VERSION ""

NS_ :

BS_:

BU_:

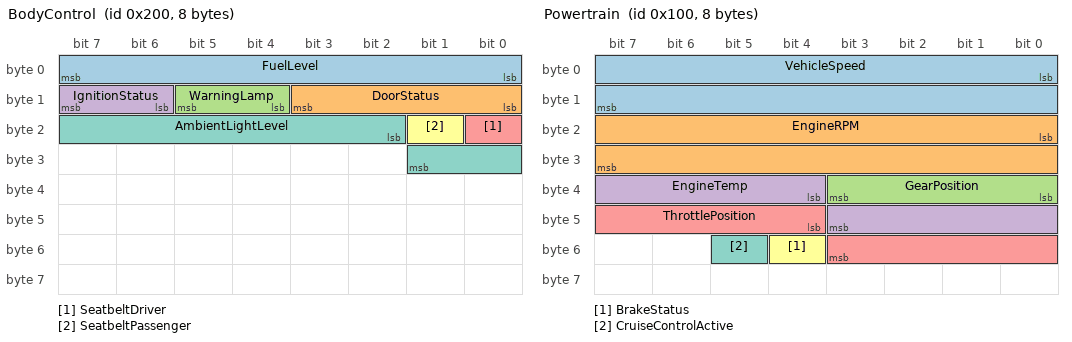
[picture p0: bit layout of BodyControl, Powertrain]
BO_ 512 BodyControl: 8 Vector__XXX
 SG_ FuelLevel : 0|8@1+ (0.392156,0) [0|100] "%" Vector__XXX
 SG_ DoorStatus : 8|4@1+ (1,0) [0|15] "" Vector__XXX
 SG_ WarningLamp : 12|2@1+ (1,0) [0|3] "" Vector__XXX
 SG_ IgnitionStatus : 14|2@1+ (1,0) [0|3] "" Vector__XXX
 SG_ SeatbeltDriver : 16|1@1+ (1,0) [0|1] "" Vector__XXX
 SG_ SeatbeltPassenger : 17|1@1+ (1,0) [0|1] "" Vector__XXX
 SG_ AmbientLightLevel : 18|8@1+ (0.392156,0) [0|100] "%" Vector__XXX

BO_ 256 Powertrain: 8 Vector__XXX
 SG_ VehicleSpeed : 0|16@1+ (0.01,0) [0|250] "km/h" Vector__XXX
 SG_ EngineRPM : 16|16@1+ (0.25,0) [0|8000] "rpm" Vector__XXX
 SG_ GearPosition : 32|4@1+ (1,0) [0|8] "" Vector__XXX
 SG_ EngineTemp : 36|8@1+ (0.5,-40) [-40|210] "degC" Vector__XXX
 SG_ ThrottlePosition : 44|8@1+ (0.392156,0) [0|100] "%" Vector__XXX
 SG_ BrakeStatus : 52|1@1+ (1,0) [0|1] "" Vector__XXX
 SG_ CruiseControlActive : 53|1@1+ (1,0) [0|1] "" Vector__XXX

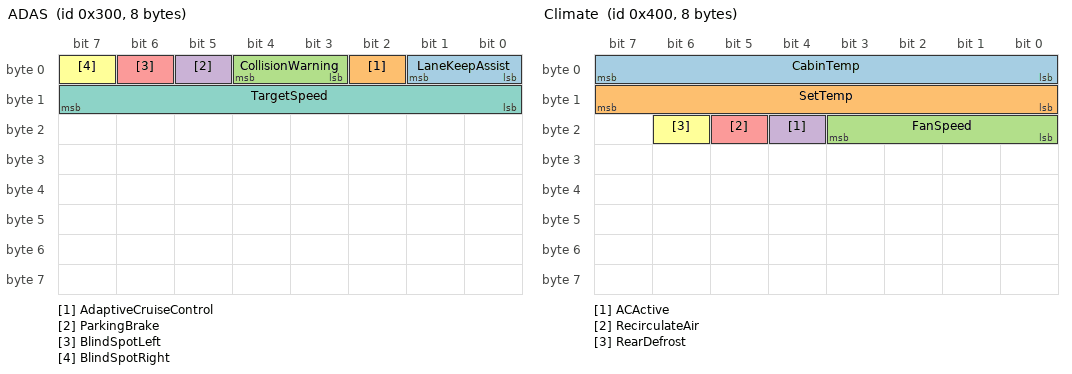
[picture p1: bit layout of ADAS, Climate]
BO_ 768 ADAS: 8 Vector__XXX
 SG_ LaneKeepAssist : 0|2@1+ (1,0) [0|3] "" Vector__XXX
 SG_ AdaptiveCruiseControl : 2|1@1+ (1,0) [0|1] "" Vector__XXX
 SG_ CollisionWarning : 3|2@1+ (1,0) [0|3] "" Vector__XXX
 SG_ ParkingBrake : 5|1@1+ (1,0) [0|1] "" Vector__XXX
 SG_ BlindSpotLeft : 6|1@1+ (1,0) [0|1] "" Vector__XXX
 SG_ BlindSpotRight : 7|1@1+ (1,0) [0|1] "" Vector__XXX
 SG_ TargetSpeed : 8|8@1+ (1,0) [0|250] "km/h" Vector__XXX

BO_ 1024 Climate: 8 Vector__XXX
 SG_ CabinTemp : 0|8@1+ (0.5,-40) [-40|80] "degC" Vector__XXX
 SG_ SetTemp : 8|8@1+ (0.5,-40) [16|30] "degC" Vector__XXX
 SG_ FanSpeed : 16|4@1+ (1,0) [0|7] "" Vector__XXX
 SG_ ACActive : 20|1@1+ (1,0) [0|1] "" Vector__XXX
 SG_ RecirculateAir : 21|1@1+ (1,0) [0|1] "" Vector__XXX
 SG_ RearDefrost : 22|1@1+ (1,0) [0|1] "" Vector__XXX
